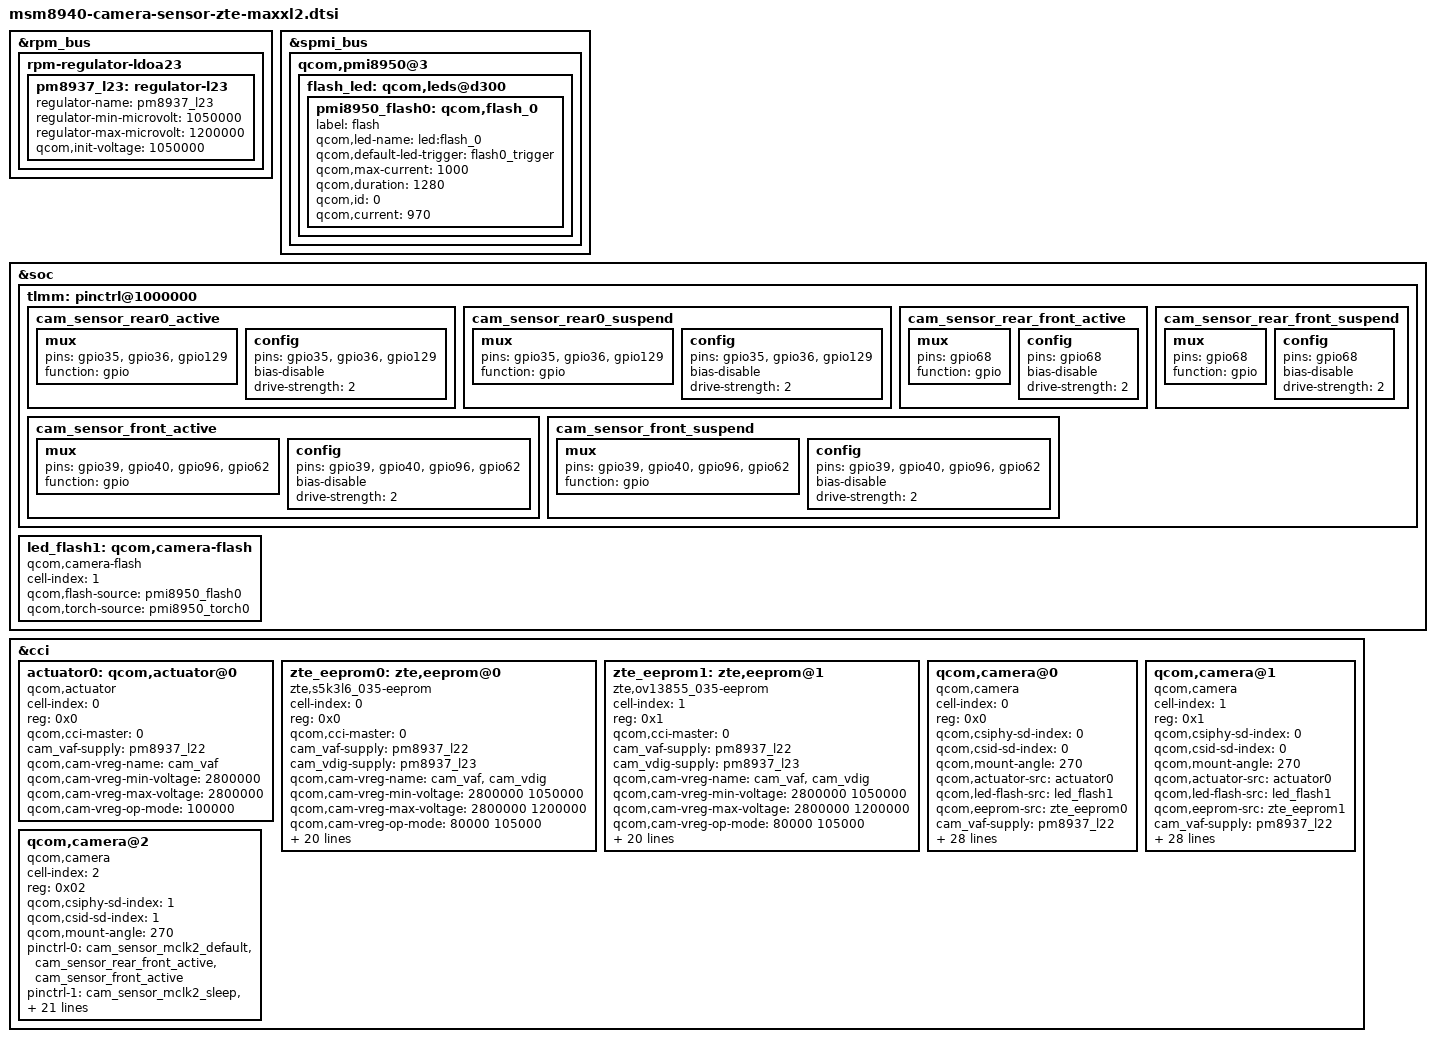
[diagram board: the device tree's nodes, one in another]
/*
* Copyright (c) 2015-2016, The Linux Foundation. All rights reserved.
*
* This program is free software; you can redistribute it and/or modify
* it under the terms of the GNU General Public License version 2 and
* only version 2 as published by the Free Software Foundation.
*
* This program is distributed in the hope that it will be useful,
* but WITHOUT ANY WARRANTY; without even the implied warranty of
* MERCHANTABILITY or FITNESS FOR A PARTICULAR PURPOSE.  See the
* GNU General Public License for more details.
*/

&rpm_bus {
	rpm-regulator-ldoa23 {
		status = "okay";
		pm8937_l23: regulator-l23 {
			regulator-name = "pm8937_l23";
			regulator-min-microvolt = <1050000>;
			regulator-max-microvolt = <1200000>;
			qcom,init-voltage = <1050000>;
			status = "okay";
		};
	};
};

&spmi_bus {
	qcom,pmi8950@3 {
		flash_led: qcom,leds@d300 {
			pmi8950_flash0: qcom,flash_0 {
				label = "flash";
				qcom,led-name = "led:flash_0";
				qcom,default-led-trigger =
						"flash0_trigger";
				qcom,max-current = <1000>;
				qcom,duration = <1280>;
				qcom,id = <0>;
				qcom,current = <970>;
			};
		};
	};
};

&soc {

	tlmm: pinctrl@1000000 {
		cam_sensor_rear0_active: cam_sensor_rear0_active {
			mux {
				pins = "gpio35", "gpio36", "gpio129";
				function = "gpio";
			};

			config {
				pins = "gpio35", "gpio36", "gpio129";
				bias-disable; /* No PULL */
				drive-strength = <2>; /* 2 MA */
			};
		};

		cam_sensor_rear0_suspend: cam_sensor_rear0_suspend{
			mux {
				pins = "gpio35", "gpio36", "gpio129";
				function = "gpio";
			};

			config {
				pins = "gpio35", "gpio36", "gpio129";
				bias-disable; /* No PULL */
				drive-strength = <2>; /* 2 MA */
			};
		};

		cam_sensor_rear_front_active: cam_sensor_rear_front_active {
			mux {
				pins = "gpio68";
				function = "gpio";
			};

			config {
				pins = "gpio68";
				bias-disable; /* No PULL */
				drive-strength = <2>; /* 2 MA */
			};
		};

		cam_sensor_rear_front_suspend: cam_sensor_rear_front_suspend{
			mux {
				pins = "gpio68";
				function = "gpio";
			};

			config {
				pins = "gpio68";
				bias-disable; /* No PULL */
				drive-strength = <2>; /* 2 MA */
			};
		};


		cam_sensor_front_active: cam_sensor_front_active {
			mux {
				pins = "gpio39", "gpio40", "gpio96", "gpio62";
				function = "gpio";
			};

			config {
				pins = "gpio39", "gpio40", "gpio96", "gpio62";
				bias-disable; /* No PULL */
				drive-strength = <2>; /* 2 MA */
			};
		};

		cam_sensor_front_suspend: cam_sensor_front_suspend{
			mux {
				pins = "gpio39", "gpio40", "gpio96", "gpio62";
				function = "gpio";
			};

			config {
				pins = "gpio39", "gpio40", "gpio96", "gpio62";
				bias-disable; /* No PULL */
				drive-strength = <2>; /* 2 MA */
			};
		};
	};

	led_flash1: qcom,camera-flash {
		cell-index = <1>;
		compatible = "qcom,camera-flash";
		qcom,flash-source = <&pmi8950_flash0>;
		qcom,torch-source = <&pmi8950_torch0>;
		status = "ok";
	};
};



&cci {

	actuator0: qcom,actuator@0 {
		cell-index = <0>;
		reg = <0x0>;
		compatible = "qcom,actuator";
		qcom,cci-master = <0>;
		cam_vaf-supply = <&pm8937_l22>;
		qcom,cam-vreg-name = "cam_vaf";
		qcom,cam-vreg-min-voltage = <2800000>;
		qcom,cam-vreg-max-voltage = <2800000>;
		qcom,cam-vreg-op-mode = <100000>;
	};

	zte_eeprom0: zte,eeprom@0 {
		cell-index = <0>;
		compatible = "zte,s5k3l6_035-eeprom";
		reg = <0x0>;
		qcom,cci-master = <0>;
		cam_vaf-supply = <&pm8937_l22>;
		cam_vdig-supply = <&pm8937_l23>;
		qcom,cam-vreg-name ="cam_vaf","cam_vdig";
		qcom,cam-vreg-min-voltage = <2800000 1050000>;
		qcom,cam-vreg-max-voltage = <2800000 1200000>;
		qcom,cam-vreg-op-mode = <80000 105000>;
		pinctrl-names = "cam_default", "cam_suspend";
		pinctrl-0 = <&cam_sensor_mclk0_default
				&cam_sensor_rear_front_active
				&cam_sensor_rear0_active>;
		pinctrl-1 = <&cam_sensor_mclk0_sleep
				&cam_sensor_rear_front_suspend
				&cam_sensor_rear0_suspend>;
		gpios = <&tlmm 26 0>,
			<&tlmm 36 0>,
			<&tlmm 35 0>,
			<&tlmm 68 0>,
			<&tlmm 129 0>;
		qcom,gpio-reset = <1>;
		qcom,gpio-standby = <2>;
		qcom,gpio-vio = <3>;
		qcom,gpio-vana = <4>;
		qcom,gpio-req-tbl-num = <0 1 2 3 4>;
		qcom,gpio-req-tbl-flags = <1 0 0 0 0>;
		qcom,gpio-req-tbl-label = "CAMIF_MCLK0",
			"CAM_RESET0",
			"CAM_STANDBY0",
			"CAM_VIO0",
			"CAM_VANA0";
		status = "ok";
		clocks = <&clock_gcc clk_mclk0_clk_src>,
				<&clock_gcc clk_gcc_camss_mclk0_clk>;
		clock-names = "cam_src_clk", "cam_clk";
		qcom,clock-rates = <24000000 0>;
	};

	zte_eeprom1: zte,eeprom@1 {
		cell-index = <1>;
		compatible = "zte,ov13855_035-eeprom";
		reg = <0x1>;
		qcom,cci-master = <0>;
		cam_vaf-supply = <&pm8937_l22>;
		cam_vdig-supply = <&pm8937_l23>;
		qcom,cam-vreg-name ="cam_vaf","cam_vdig";
		qcom,cam-vreg-min-voltage = <2800000 1050000>;
		qcom,cam-vreg-max-voltage = <2800000 1200000>;
		qcom,cam-vreg-op-mode = <80000 105000>;
		pinctrl-names = "cam_default", "cam_suspend";
		pinctrl-0 = <&cam_sensor_mclk0_default
				&cam_sensor_rear_front_active
				&cam_sensor_rear0_active>;
		pinctrl-1 = <&cam_sensor_mclk0_sleep
				&cam_sensor_rear_front_suspend
				&cam_sensor_rear0_suspend>;
		gpios = <&tlmm 26 0>,
			<&tlmm 36 0>,
			<&tlmm 35 0>,
			<&tlmm 68 0>,
			<&tlmm 129 0>;
		qcom,gpio-reset = <1>;
		qcom,gpio-standby = <2>;
		qcom,gpio-vio = <3>;
		qcom,gpio-vana = <4>;
		qcom,gpio-req-tbl-num = <0 1 2 3 4>;
		qcom,gpio-req-tbl-flags = <1 0 0 0 0>;
		qcom,gpio-req-tbl-label = "CAMIF_MCLK0",
			"CAM_RESET0",
			"CAM_STANDBY0",
			"CAM_VIO0",
			"CAM_VANA0";
		status = "ok";
		clocks = <&clock_gcc clk_mclk0_clk_src>,
				<&clock_gcc clk_gcc_camss_mclk0_clk>;
		clock-names = "cam_src_clk", "cam_clk";
		qcom,clock-rates = <24000000 0>;
	};


	qcom,camera@0 {
		cell-index = <0>;
		compatible = "qcom,camera";
		reg = <0x0>;
		qcom,csiphy-sd-index = <0>;
		qcom,csid-sd-index = <0>;
		qcom,mount-angle = <270>;
		qcom,actuator-src = <&actuator0>;
		qcom,led-flash-src = <&led_flash1>;
		qcom,eeprom-src = <&zte_eeprom0>;
		cam_vaf-supply = <&pm8937_l22>;
		cam_vdig-supply = <&pm8937_l23>;
		qcom,cam-vreg-name ="cam_vaf","cam_vdig";
		qcom,cam-vreg-min-voltage = <2800000 1050000>;
		qcom,cam-vreg-max-voltage = <2800000 1200000>;
		qcom,cam-vreg-op-mode = <80000 105000>;
		pinctrl-names = "cam_default", "cam_suspend";
		pinctrl-0 = <&cam_sensor_mclk0_default
				&cam_sensor_rear_front_active
				&cam_sensor_rear0_active>;
		pinctrl-1 = <&cam_sensor_mclk0_sleep
				&cam_sensor_rear_front_suspend
				&cam_sensor_rear0_suspend>;
		gpios = <&tlmm 26 0>,
			<&tlmm 36 0>,
			<&tlmm 35 0>,
			<&tlmm 68 0>,
			<&tlmm 129 0>;
		qcom,gpio-reset = <1>;
		qcom,gpio-standby = <2>;
		qcom,gpio-vio = <3>;
		qcom,gpio-vana = <4>;
		qcom,gpio-req-tbl-num = <0 1 2 3 4>;
		qcom,gpio-req-tbl-flags = <1 0 0 0 0>;
		qcom,gpio-req-tbl-label = "CAMIF_MCLK0",
			"CAM_RESET0",
			"CAM_STANDBY0",
			"CAM_VIO0",
			"CAM_VANA0";
		qcom,sensor-position = <0>;
		qcom,sensor-mode = <0>;
		qcom,cci-master = <0>;
		status = "ok";
		clocks = <&clock_gcc clk_mclk0_clk_src>,
				<&clock_gcc clk_gcc_camss_mclk0_clk>;
		clock-names = "cam_src_clk", "cam_clk";
		qcom,clock-rates = <24000000 0>;
	};

	qcom,camera@1 {
		cell-index = <1>;
		compatible = "qcom,camera";
		reg = <0x1>;
		qcom,csiphy-sd-index = <0>;
		qcom,csid-sd-index = <0>;
		qcom,mount-angle = <270>;
		qcom,actuator-src = <&actuator0>;
		qcom,led-flash-src = <&led_flash1>;
		qcom,eeprom-src = <&zte_eeprom1>;
		cam_vaf-supply = <&pm8937_l22>;
		cam_vdig-supply = <&pm8937_l23>;
		qcom,cam-vreg-name ="cam_vaf","cam_vdig";
		qcom,cam-vreg-min-voltage = <2800000 1050000>;
		qcom,cam-vreg-max-voltage = <2800000 1200000>;
		qcom,cam-vreg-op-mode = <80000 105000>;
		pinctrl-names = "cam_default", "cam_suspend";
		pinctrl-0 = <&cam_sensor_mclk0_default
				&cam_sensor_rear_front_active
				&cam_sensor_rear0_active>;
		pinctrl-1 = <&cam_sensor_mclk0_sleep
				&cam_sensor_rear_front_suspend
				&cam_sensor_rear0_suspend>;
		gpios = <&tlmm 26 0>,
			<&tlmm 36 0>,
			<&tlmm 35 0>,
			<&tlmm 68 0>,
			<&tlmm 129 0>;
		qcom,gpio-reset = <1>;
		qcom,gpio-standby = <2>;
		qcom,gpio-vio = <3>;
		qcom,gpio-vana = <4>;
		qcom,gpio-req-tbl-num = <0 1 2 3 4>;
		qcom,gpio-req-tbl-flags = <1 0 0 0 0>;
		qcom,gpio-req-tbl-label = "CAMIF_MCLK0",
			"CAM_RESET0",
			"CAM_STANDBY0",
			"CAM_VIO0",
			"CAM_VANA0";
		qcom,sensor-position = <0>;
		qcom,sensor-mode = <0>;
		qcom,cci-master = <0>;
		status = "ok";
		clocks = <&clock_gcc clk_mclk0_clk_src>,
				<&clock_gcc clk_gcc_camss_mclk0_clk>;
		clock-names = "cam_src_clk", "cam_clk";
		qcom,clock-rates = <24000000 0>;
	};


	qcom,camera@2 {
		cell-index = <2>;
		compatible = "qcom,camera";
		reg = <0x02>;
		qcom,csiphy-sd-index = <1>;
		qcom,csid-sd-index = <1>;
		qcom,mount-angle = <270>;
		pinctrl-names = "cam_default", "cam_suspend";
		pinctrl-0 = <&cam_sensor_mclk2_default
				&cam_sensor_rear_front_active
				&cam_sensor_front_active>;
		pinctrl-1 = <&cam_sensor_mclk2_sleep
				&cam_sensor_rear_front_suspend
				&cam_sensor_front_suspend>;
		gpios = <&tlmm 28 0>,
			<&tlmm 40 0>,
			<&tlmm 39 0>,
			<&tlmm 68 0>,
			<&tlmm 96 0>,
			<&tlmm 62 0>,
			<&tlmm 129 0>;
		qcom,gpio-reset = <1>;
		qcom,gpio-standby = <2>;
		qcom,gpio-vio = <3>;
		qcom,gpio-vana = <4>;
		qcom,gpio-vdig = <5>;
		qcom,gpio-custom1 = <6>;
		qcom,gpio-req-tbl-num = <0 1 2 3 4 5 6>;
		qcom,gpio-req-tbl-flags = <1 0 0 0 0 0 0>;
		qcom,gpio-req-tbl-label = "CAMIF_MCLK2",
					  "CAM_RESET2",
					  "CAM_STANDBY2",
					  "CAM_VIO2",
					  "CAM_VANA2",
					  "CAM_VDIG2",
					  "CAM_CUSTOM1";
		qcom,sensor-position = <1>;
		qcom,sensor-mode = <0>;
		qcom,cci-master = <0>;
		status = "ok";
		clocks = <&clock_gcc clk_mclk2_clk_src>,
			<&clock_gcc clk_gcc_camss_mclk2_clk>;
		clock-names = "cam_src_clk", "cam_clk";
		qcom,clock-rates = <24000000 0>;
	};
};
